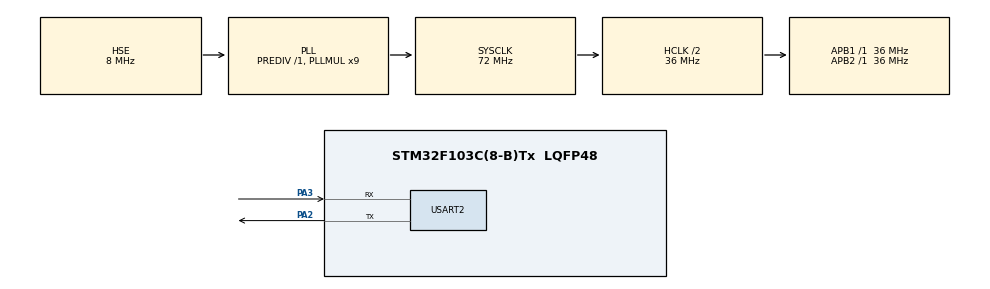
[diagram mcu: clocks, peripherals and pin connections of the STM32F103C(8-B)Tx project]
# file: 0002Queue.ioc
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FREERTOS.Queues01=myQueue01,14,uint32_t,0,Dynamic,NULL,NULL
FREERTOS.Tasks01=defaultTask,0,128,StartDefaultTask,Default,NULL,Dynamic,NULL,NULL
Mcu.Family=STM32F1
Mcu.Name=STM32F103C(8-B)Tx
Mcu.Package=LQFP48
NVIC.PriorityGroup=NVIC_PRIORITYGROUP_4
NVIC.TIM4_IRQn=true\:15\:0\:false\:false\:true\:false\:false\:true
NVIC.TimeBase=TIM4_IRQn
NVIC.TimeBaseIP=TIM4
NVIC.USART2_IRQn=true\:5\:0\:false\:false\:true\:true\:true\:true
PA13.Mode=Serial_Wire
PA13.Signal=SYS_JTMS-SWDIO
PA14.Mode=Serial_Wire
PA14.Signal=SYS_JTCK-SWCLK
PA2.Mode=Asynchronous
PA2.Signal=USART2_TX
PA3.Mode=Asynchronous
PA3.Signal=USART2_RX
PD0-OSC_IN.Mode=HSE-External-Oscillator
PD0-OSC_IN.Signal=RCC_OSC_IN
PD1-OSC_OUT.Mode=HSE-External-Oscillator
PD1-OSC_OUT.Signal=RCC_OSC_OUT
ProjectManager.HeapSize=0x200
ProjectManager.StackSize=0x400
ProjectManager.TargetToolchain=STM32CubeIDE
RCC.AHBCLKDivider=RCC_SYSCLK_DIV2
RCC.AHBFreq_Value=36000000
RCC.APB1Freq_Value=36000000
RCC.APB1TimFreq_Value=36000000
RCC.APB2Freq_Value=36000000
RCC.APB2TimFreq_Value=36000000
RCC.HCLKFreq_Value=36000000
RCC.PLLMUL=RCC_PLL_MUL9
RCC.PLLSourceVirtual=RCC_PLLSOURCE_HSE
RCC.SYSCLKFreq_VALUE=72000000
RCC.SYSCLKSource=RCC_SYSCLKSOURCE_PLLCLK
RCC.USBFreq_Value=72000000
USART2.VirtualMode=VM_ASYNC
VP_FREERTOS_VS_CMSIS_V1.Mode=CMSIS_V1
VP_SYS_VS_tim4.Mode=TIM4
board=custom

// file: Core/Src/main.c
/* USER CODE BEGIN Header */
/**
  ******************************************************************************
  * @file           : main.c
  * @brief          : Main program body
  ******************************************************************************
  * @attention
  *
  * <h2><center>&copy; Copyright (c) 2022 STMicroelectronics.
  * All rights reserved.</center></h2>
  *
  * This software component is licensed by ST under BSD 3-Clause license,
  * the "License"; You may not use this file except in compliance with the
  * License. You may obtain a copy of the License at:
  *                        opensource.org/licenses/BSD-3-Clause
  *
  ******************************************************************************
  */
/* USER CODE END Header */
#include "main.h"
#include "cmsis_os.h"

/* USER CODE BEGIN Includes */
#include "string.h"
/* USER CODE END Includes */

UART_HandleTypeDef huart2;

osThreadId defaultTaskHandle;
osMessageQId myQueue01Handle;
/* USER CODE BEGIN PV */
TaskHandle_t Task1Handle;
QueueHandle_t Queue2Hanle;
uint32_t Rx_data;
uint32_t Recv_ISR_data;
osEvent Recv_task_data;
char Recv_data[20];
/* USER CODE END PV */

void SystemClock_Config(void);
static void MX_GPIO_Init(void);
static void MX_USART2_UART_Init(void);
void StartDefaultTask(void const * argument);

/* USER CODE BEGIN PFP */
void Task1Func(void *Param);
/* USER CODE END PFP */

int main(void)
{

  /* MCU Configuration--------------------------------------------------------*/

  /* Reset of all peripherals, Initializes the Flash interface and the Systick. */
  HAL_Init();

  /* Configure the system clock */
  SystemClock_Config();

  /* Initialize all configured peripherals */
  MX_GPIO_Init();
  MX_USART2_UART_Init();

  /* Create the queue(s) */
  /* definition and creation of myQueue01 */
  osMessageQDef(myQueue01, 14, uint32_t);
  myQueue01Handle = osMessageCreate(osMessageQ(myQueue01), NULL);

  /* USER CODE BEGIN RTOS_QUEUES */
  Queue2Hanle = xQueueCreate(9, sizeof(uint32_t));  // queue của freertos

  /* add queues, ... */
  /* USER CODE END RTOS_QUEUES */

  /* Create the thread(s) */
  /* definition and creation of defaultTask */
  osThreadDef(defaultTask, StartDefaultTask, osPriorityNormal, 0, 128);
  defaultTaskHandle = osThreadCreate(osThread(defaultTask), NULL);

  /* USER CODE BEGIN RTOS_THREADS */
  xTaskCreate(Task1Func, "Task1", 128, NULL, 2, &Task1Handle);
  /* add threads, ... */
  /* USER CODE END RTOS_THREADS */

  /* Start scheduler */
  osKernelStart();

  /* We should never get here as control is now taken by the scheduler */
  /* Infinite loop */
  while (1)
  {

  }
}

void SystemClock_Config(void)
{
  RCC_OscInitTypeDef RCC_OscInitStruct = {0};
  RCC_ClkInitTypeDef RCC_ClkInitStruct = {0};

  /** Initializes the RCC Oscillators according to the specified parameters
  * in the RCC_OscInitTypeDef structure.
  */
  RCC_OscInitStruct.OscillatorType = RCC_OSCILLATORTYPE_HSE;
  RCC_OscInitStruct.HSEState = RCC_HSE_ON;
  RCC_OscInitStruct.HSEPredivValue = RCC_HSE_PREDIV_DIV1;
  RCC_OscInitStruct.HSIState = RCC_HSI_ON;
  RCC_OscInitStruct.PLL.PLLState = RCC_PLL_ON;
  RCC_OscInitStruct.PLL.PLLSource = RCC_PLLSOURCE_HSE;
  RCC_OscInitStruct.PLL.PLLMUL = RCC_PLL_MUL9;
  if (HAL_RCC_OscConfig(&RCC_OscInitStruct) != HAL_OK)
  {
    Error_Handler();
  }
  /** Initializes the CPU, AHB and APB buses clocks
  */
  RCC_ClkInitStruct.ClockType = RCC_CLOCKTYPE_HCLK|RCC_CLOCKTYPE_SYSCLK
                              |RCC_CLOCKTYPE_PCLK1|RCC_CLOCKTYPE_PCLK2;
  RCC_ClkInitStruct.SYSCLKSource = RCC_SYSCLKSOURCE_PLLCLK;
  RCC_ClkInitStruct.AHBCLKDivider = RCC_SYSCLK_DIV2;
  RCC_ClkInitStruct.APB1CLKDivider = RCC_HCLK_DIV1;
  RCC_ClkInitStruct.APB2CLKDivider = RCC_HCLK_DIV1;

  if (HAL_RCC_ClockConfig(&RCC_ClkInitStruct, FLASH_LATENCY_2) != HAL_OK)
  {
    Error_Handler();
  }
}

static void MX_USART2_UART_Init(void)
{

  huart2.Instance = USART2;
  huart2.Init.BaudRate = 115200;
  huart2.Init.WordLength = UART_WORDLENGTH_8B;
  huart2.Init.StopBits = UART_STOPBITS_1;
  huart2.Init.Parity = UART_PARITY_NONE;
  huart2.Init.Mode = UART_MODE_TX_RX;
  huart2.Init.HwFlowCtl = UART_HWCONTROL_NONE;
  huart2.Init.OverSampling = UART_OVERSAMPLING_16;
  if (HAL_UART_Init(&huart2) != HAL_OK)
  {
    Error_Handler();
  }

}

static void MX_GPIO_Init(void)
{

  /* GPIO Ports Clock Enable */
  __HAL_RCC_GPIOD_CLK_ENABLE();
  __HAL_RCC_GPIOA_CLK_ENABLE();

}

/* USER CODE BEGIN 4 */
// Task Recive
void Task1Func(void * Param)
{

  while(1)
  {
	  Recv_task_data = osMessageGet(myQueue01Handle, osWaitForever);
      xQueueReceive(Queue2Hanle, &Recv_data, osWaitForever);
  }
}
/* USER CODE END 4 */

void StartDefaultTask(void const * argument)
{
  /* USER CODE BEGIN 5 */
	uint32_t Task_data = 1999;
	char Array_data[20] = "HelloVanTho";
  /* Infinite loop */
  for(;;)
  {
    osMessagePut(myQueue01Handle, Task_data, 10);
    xQueueSendFromISR(Queue2Hanle,(void *) &Array_data,NULL);
    osDelay(2000);
    Task_data ++;
  }
  /* USER CODE END 5 */
}

void HAL_TIM_PeriodElapsedCallback(TIM_HandleTypeDef *htim)
{
  if (htim->Instance == TIM4) {
    HAL_IncTick();
  }
}

void Error_Handler(void)
{
  __disable_irq();
  while (1)
  {
  }
}

/************************ (C) COPYRIGHT STMicroelectronics *****END OF FILE****/
